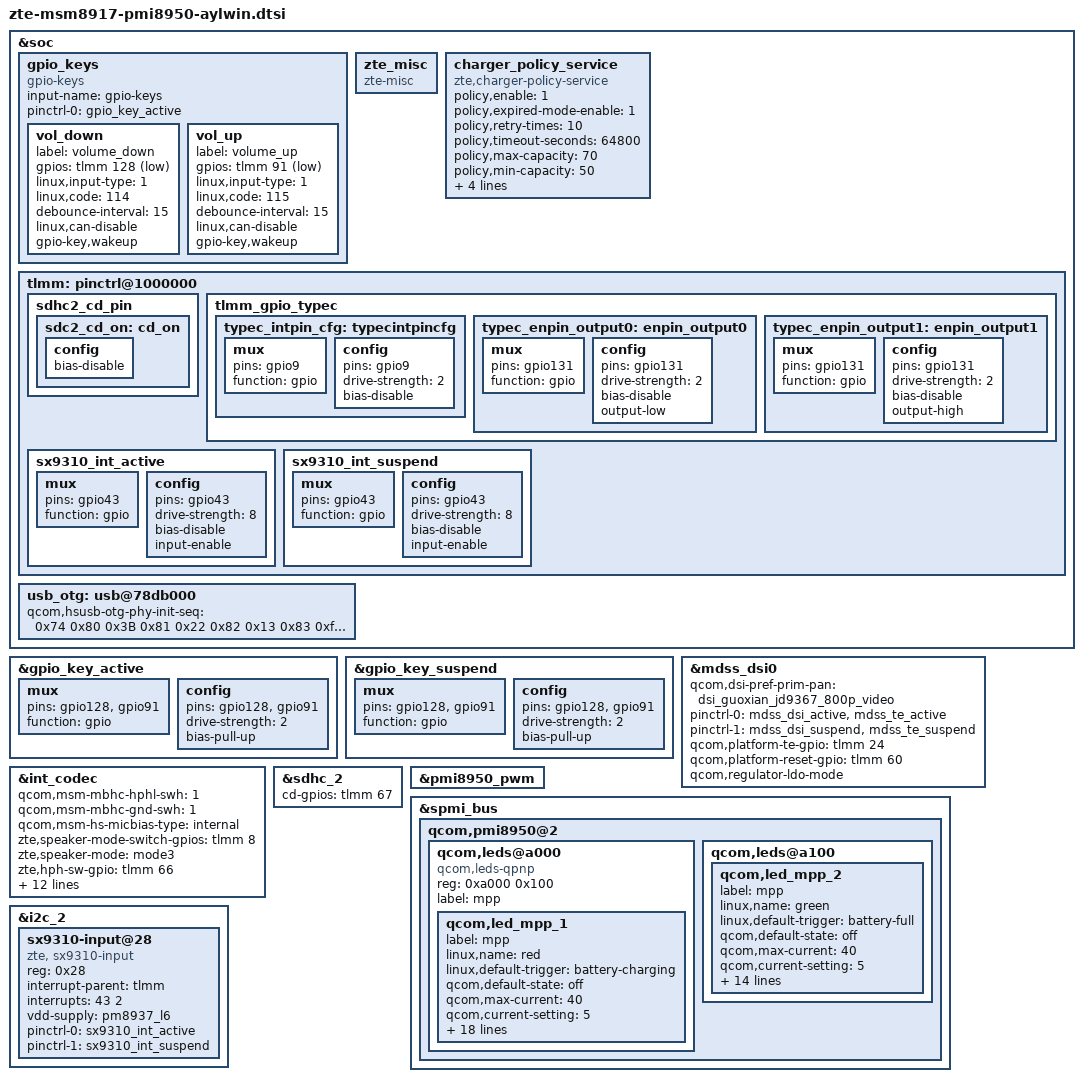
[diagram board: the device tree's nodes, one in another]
/*
 * Copyright (c) 2016, The Linux Foundation. All rights reserved.
 *
 * This program is free software; you can redistribute it and/or modify
 * it under the terms of the GNU General Public License version 2 and
 * only version 2 as published by the Free Software Foundation.
 *
 * This program is distributed in the hope that it will be useful,
 * but WITHOUT ANY WARRANTY; without even the implied warranty of
 * MERCHANTABILITY or FITNESS FOR A PARTICULAR PURPOSE.  See the
 * GNU General Public License for more details.
 */

/*
* device tree for zte aylwin board
*/

#include "zte-msm8917-camera-sensor-aylwin.dtsi"
#include "zte-usb-type-c.dtsi"
&soc {
	gpio_keys {
		compatible = "gpio-keys";
		input-name = "gpio-keys";
		pinctrl-names = "default";
		pinctrl-0 = <&gpio_key_active>;
		/delete-node/camera_focus;
		/delete-node/camera_snapshot;

		vol_down {
			label = "volume_down";
			gpios = <&tlmm 128 0x1>;
			linux,input-type = <1>;
			linux,code = <114>;
			debounce-interval = <15>;
			linux,can-disable;
			gpio-key,wakeup;
		};

		vol_up {
			label = "volume_up";
			gpios = <&tlmm 91 0x1>;
			linux,input-type = <1>;
			linux,code = <115>;
			debounce-interval = <15>;
			linux,can-disable;
			gpio-key,wakeup;
		};
	};
	zte_misc {
		compatible = "zte-misc";
	};

};

&soc {
	charger_policy_service {
		compatible = "zte,charger-policy-service";
		policy,enable = <1>;
		policy,expired-mode-enable = <1>;
		policy,retry-times = <10>;
		policy,timeout-seconds = <64800>;/* 18 hours */
		policy,max-capacity = <70>;
		policy,min-capacity = <50>;
		policy,demo-max-capacity = <35>;
		policy,demo-min-capacity = <30>;
		policy,bms-phy-name = "bms";
		policy,battery-phy-name = "battery";
	};
};

&gpio_key_active {
	mux {
		pins = "gpio128", "gpio91";
		function = "gpio";
	};
	config {
		pins = "gpio128", "gpio91";
		drive-strength = <2>;
		bias-pull-up;
	};
};
&gpio_key_suspend {
	mux {
		pins = "gpio128", "gpio91";
		function = "gpio";
	};
	config {
		pins = "gpio128", "gpio91";
		drive-strength = <2>;
		bias-pull-up;
	};
};

#include "dsi-panel-kingdisplay-hx8394-hsd-8p0-800p-video.dtsi"
#include "dsi-panel-zte-guoxian-jd9367-qunchuang-8p0-900p-video-aylwin.dtsi"
#include "dsi-panel-zte-guoxian-jd9365-qunchuang-8p0-900p-video-aylwin.dtsi"
&mdss_dsi0 {
	qcom,dsi-pref-prim-pan = <&dsi_guoxian_jd9367_800p_video>;
	pinctrl-names = "mdss_default", "mdss_sleep";
	pinctrl-0 = <&mdss_dsi_active &mdss_te_active>;
	pinctrl-1 = <&mdss_dsi_suspend &mdss_te_suspend>;

	qcom,platform-te-gpio = <&tlmm 24 0>;
	qcom,platform-reset-gpio = <&tlmm 60 0>;

	qcom,regulator-ldo-mode;
};

&int_codec {
	qcom,msm-mbhc-hphl-swh = <1>;
	qcom,msm-mbhc-gnd-swh = <1>;
	qcom,msm-hs-micbias-type = "internal";
	zte,speaker-mode-switch-gpios = <&tlmm 8 0x0>;
	zte,speaker-mode = "mode3";
	zte,hph-sw-gpio = <&tlmm 66 0x0>;
	qcom,audio-routing =
			"RX_BIAS", "MCLK",
			"SPK_RX_BIAS", "MCLK",
			"INT_LDO_H", "MCLK",
			"RX_I2S_CLK", "MCLK",
			"TX_I2S_CLK", "MCLK",
			"MIC BIAS External", "Handset Mic",
			"MIC BIAS Internal2", "Headset Mic",
			"MIC BIAS External", "Secondary Mic",
			"AMIC1", "MIC BIAS External",
			"AMIC2", "MIC BIAS Internal2",
			"AMIC3", "MIC BIAS External",
			"ADC1_IN", "ADC1_OUT",
			"ADC2_IN", "ADC2_OUT",
			"ADC3_IN", "ADC3_OUT",
			"PDM_IN_RX1", "PDM_OUT_RX1",
			"PDM_IN_RX2", "PDM_OUT_RX2",
			"PDM_IN_RX3", "PDM_OUT_RX3";
			/* "WSA_SPK OUT", "VDD_WSA_SWITCH", */
			/* "SpkrMono WSA_IN", "WSA_SPK OUT"; */
};

/*zteadd  for SD cd pin start*/
&sdhc_2 {
	cd-gpios = <&tlmm 67 0x0>;
};
&soc {
	tlmm: pinctrl@1000000 {
		sdhc2_cd_pin {
		sdc2_cd_on: cd_on {
			config {
				/delete-property/ bias-pull-up;
				bias-disable;
				};
			};
			};
		};
	usb_otg: usb@78db000 {
		qcom,hsusb-otg-phy-init-seq =
			<0x74 0x80 0x3B 0x81 0x22 0x82 0x13 0x83 0xffffffff>;
	};
};

&pmi8950_pwm {
		status = "okay";
		};
&spmi_bus {
	qcom,pmi8950@2 {
		qcom,leds@a000 {
			compatible = "qcom,leds-qpnp";
			reg = <0xa000 0x100>;
			label = "mpp";
			status = "okay";
			qcom,led_mpp_1 {	/* red led */
				label = "mpp";
				linux,name = "red";
				linux,default-trigger = "battery-charging";	/* org="bkl-trigger"; */
				qcom,default-state = "off";
				qcom,max-current = <40>;
				qcom,current-setting = <5>;
				qcom,id = <6>;				/* in leds-qpnp.c enum QPNP_ID_LED_MPP(6) */
				qcom,source-sel = <11>; /* connect MPP to inverted DTEST2 for PMI8950 */
				qcom,src-sel = <10>;
				qcom,mode-ctrl = <0x10>;	/* operation mode, default 0x60 = Mode Sink (org=0x10)*/
				qcom,pwm-channel = <0>;
				qcom,pwm-us = <1000>;
				qcom,vin-ctrl = <0x00>;		/* select input source, 0 to 3 */
				qcom,duty-pcts = <50>;
				qcom,start-idx = <1>;
				qcom,lut-flags = <3>;
				qcom,pause-lo = <0>;
				qcom,pause-hi = <0>;
				qcom,ramp-step-ms = <255>;
				qcom,mode = "pwm";
				qcom,use-blink;
				pwms = <&pmi8950_pwm 0 0>;
				qcom,pwm-names = "red-led";
				zte,is-operator-sprint = "no";
			};
		};

		qcom,leds@a100 {
			status = "okay";
			qcom,led_mpp_2 {	/* green led */
				label = "mpp";
				linux,name = "green";
				linux,default-trigger = "battery-full";
				qcom,default-state = "off";
				qcom,max-current = <40>;
				qcom,current-setting = <5>;
				qcom,id = <6>;
				#qcom,source-sel = <8>;
				qcom,source-sel = <10>; /* connect MPP to DTEST2*/
				qcom,src-sel = <10>;

				qcom,mode-ctrl = <0x60>;
				qcom,pwm-channel = <0>;
				qcom,pwm-us = <1000>;
				qcom,vin-ctrl = <0x00>;
				qcom,duty-pcts = <50>;
				qcom,mode = "pwm";
				qcom,use-blink;
				pwms = <&pmi8950_pwm 0 0>;
				qcom,pwm-names = "green-led";
				zte,is-operator-sprint = "no";
			};
		};
	};
};

&tlmm {
/* zte typec */
	tlmm_gpio_typec {
		typec_intpin_cfg: typecintpincfg {
				mux {
					pins = "gpio9";
					function = "gpio";
				};
				config {
					pins = "gpio9";
					drive-strength = <2>;
					bias-disable;
				};
		};
		typec_enpin_output0: enpin_output0 {
				mux {
					pins = "gpio131";
					function = "gpio";
				};
				config {
					pins = "gpio131";
					drive-strength = <2>;
					bias-disable;
					output-low;
				};
		};
		typec_enpin_output1: enpin_output1 {
				mux {
					pins = "gpio131";
					function = "gpio";
				};
				config {
					pins = "gpio131";
					drive-strength = <2>;
					bias-disable;
					output-high;
				};
		};
	};
/*zte typec */
	sx9310_int_active: sx9310_int_active {
		mux {
			pins = "gpio43";
			function = "gpio";
		};
		config {
			pins = "gpio43";
			drive-strength = <8>;
			bias-disable;
			input-enable;
		};
	};
	sx9310_int_suspend: sx9310_int_suspend {
		mux {
			pins = "gpio43";
			function = "gpio";
		};
		config {
			pins = "gpio43";
			drive-strength = <8>;
			bias-disable;
			input-enable;
		};
	};
};

&i2c_2 { /* BLSP1 QUP2 */
	status = "okay";
	sx9310-input@28 {
		compatible = "zte, sx9310-input";
		reg = <0x28>;
		interrupt-parent = <&tlmm>;
		interrupts = <43 2>;
		interrupt-names = "sx9310_irq";
		vdd-supply = <&pm8937_l6>;
		pinctrl-names = "sx9310_active", "sx9310_sleep";
		pinctrl-0 = <&sx9310_int_active>;
		pinctrl-1 = <&sx9310_int_suspend >;
	};
};
